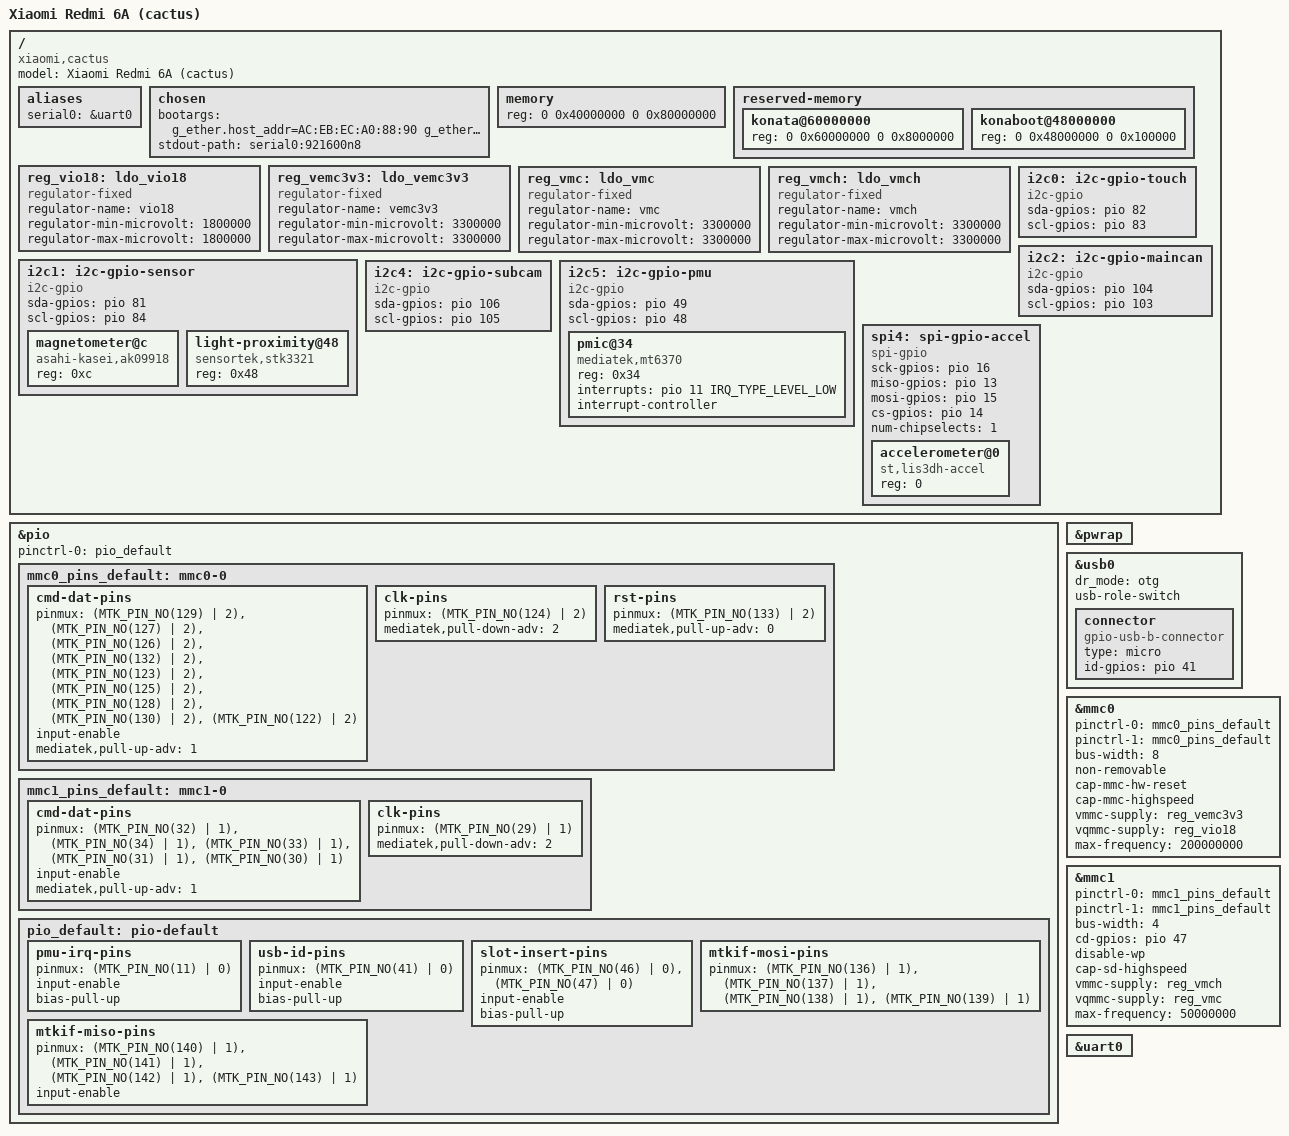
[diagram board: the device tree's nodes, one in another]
// SPDX-License-Identifier: GPL-2.0

/dts-v1/;

#include "mt6762m.dtsi"

#include <dt-bindings/gpio/gpio.h>
#include <dt-bindings/input/input.h>
#include <dt-bindings/pinctrl/mt65xx.h>

/ {
	compatible = "xiaomi,cactus", "mediatek,mt6762m", "mediatek,mt6765";
	model = "Xiaomi Redmi 6A (cactus)";

	aliases {
		serial0 = &uart0;
	};

	chosen {
		bootargs = "\
g_ether.host_addr=AC:EB:EC:A0:88:90 g_ether.dev_addr=DE:AD:BE:EF:47:77 \
clk_ignore_unused earlycon console=ttyS0,921600 root=/dev/mmcblk1p2 rootwait";
		stdout-path = "serial0:921600n8";
	};

	memory {
		device_type = "memory";
		reg = <0 0x40000000 0 0x80000000>;
	};

	reserved-memory {
		#address-cells = <2>;
		#size-cells = <2>;
		ranges;

		/* konata's 128 MiB of reserved memory */
		konata@60000000 {
			reg = <0 0x60000000 0 0x8000000>;
		};

		/* My special bootloader */
		konaboot@48000000 {
			reg = <0 0x48000000 0 0x100000>;
		};
	};

	/* dummy regulators -- needs to be from the MT6357 PMIC node! */
	reg_vio18: ldo_vio18 {
		compatible = "regulator-fixed";
		regulator-name = "vio18";
		regulator-min-microvolt = <1800000>;
		regulator-max-microvolt = <1800000>;
	};

	reg_vemc3v3: ldo_vemc3v3 {
		compatible = "regulator-fixed";
		regulator-name = "vemc3v3";
		regulator-min-microvolt = <3300000>;
		regulator-max-microvolt = <3300000>;
	};

	reg_vmc: ldo_vmc {
		compatible = "regulator-fixed";
		regulator-name = "vmc";
		regulator-min-microvolt = <3300000>;
		regulator-max-microvolt = <3300000>;
	};

	reg_vmch: ldo_vmch {
		compatible = "regulator-fixed";
		regulator-name = "vmch";
		regulator-min-microvolt = <3300000>;
		regulator-max-microvolt = <3300000>;
	};

	/* i2c gpio -- need to make the hw i2c work */
	i2c0: i2c-gpio-touch {
		compatible = "i2c-gpio";
		sda-gpios = <&pio 82 (GPIO_ACTIVE_HIGH|GPIO_OPEN_DRAIN)>;
		scl-gpios = <&pio 83 (GPIO_ACTIVE_HIGH|GPIO_OPEN_DRAIN)>;
	};

	i2c1: i2c-gpio-sensor {
		compatible = "i2c-gpio";
		sda-gpios = <&pio 81 (GPIO_ACTIVE_HIGH|GPIO_OPEN_DRAIN)>;
		scl-gpios = <&pio 84 (GPIO_ACTIVE_HIGH|GPIO_OPEN_DRAIN)>;
	};

	i2c2: i2c-gpio-maincan {
		compatible = "i2c-gpio";
		sda-gpios = <&pio 104 (GPIO_ACTIVE_HIGH|GPIO_OPEN_DRAIN)>;
		scl-gpios = <&pio 103 (GPIO_ACTIVE_HIGH|GPIO_OPEN_DRAIN)>;
	};

	i2c4: i2c-gpio-subcam {
		compatible = "i2c-gpio";
		sda-gpios = <&pio 106 (GPIO_ACTIVE_HIGH|GPIO_OPEN_DRAIN)>;
		scl-gpios = <&pio 105 (GPIO_ACTIVE_HIGH|GPIO_OPEN_DRAIN)>;
	};

	i2c5: i2c-gpio-pmu {
		compatible = "i2c-gpio";
		sda-gpios = <&pio 49 (GPIO_ACTIVE_HIGH|GPIO_OPEN_DRAIN)>;
		scl-gpios = <&pio 48 (GPIO_ACTIVE_HIGH|GPIO_OPEN_DRAIN)>;
	};

	/* spi gpio --- need to make the hw spi work */
	spi4: spi-gpio-accel {
		compatible = "spi-gpio";
		sck-gpios = <&pio 16 0>;
		miso-gpios = <&pio 13 0>;
		mosi-gpios = <&pio 15 0>;
		cs-gpios = <&pio 14 0>;
		num-chipselects = <1>;
	};
};

&pio {
	pinctrl-0 = <&pio_default>;
	pinctrl-names = "default";

	mmc0_pins_default: mmc0-0 {
		cmd-dat-pins {
			pinmux = <(MTK_PIN_NO(129) | 2)>,
			         <(MTK_PIN_NO(127) | 2)>,
			         <(MTK_PIN_NO(126) | 2)>,
			         <(MTK_PIN_NO(132) | 2)>,
			         <(MTK_PIN_NO(123) | 2)>,
			         <(MTK_PIN_NO(125) | 2)>,
			         <(MTK_PIN_NO(128) | 2)>,
			         <(MTK_PIN_NO(130) | 2)>,
			         <(MTK_PIN_NO(122) | 2)>;
			input-enable;
			mediatek,pull-up-adv = <1>;
		};
		clk-pins {
			pinmux = <(MTK_PIN_NO(124) | 2)>;
			mediatek,pull-down-adv = <2>;
		};
		rst-pins {
			pinmux = <(MTK_PIN_NO(133) | 2)>;
			mediatek,pull-up-adv = <0>;
		};
	};

	mmc1_pins_default: mmc1-0 {
		cmd-dat-pins {
			pinmux = <(MTK_PIN_NO(32) | 1)>,
			         <(MTK_PIN_NO(34) | 1)>,
			         <(MTK_PIN_NO(33) | 1)>,
			         <(MTK_PIN_NO(31) | 1)>,
			         <(MTK_PIN_NO(30) | 1)>;
			input-enable;
			mediatek,pull-up-adv = <1>;
		};
		clk-pins {
			pinmux = <(MTK_PIN_NO(29) | 1)>;
			mediatek,pull-down-adv = <2>;
		};
	};

	pio_default: pio-default {
		pmu-irq-pins {
			pinmux = <(MTK_PIN_NO(11) | 0)>;
			input-enable;
			bias-pull-up;
		};

		usb-id-pins {
			pinmux = <(MTK_PIN_NO(41) | 0)>; /* 1 for IDDIG */
			input-enable;
			bias-pull-up;
		};

		slot-insert-pins {
			pinmux = <(MTK_PIN_NO(46) | 0)>, /* SIM2 */
			         <(MTK_PIN_NO(47) | 0)>; /* SIM1/microSD */
			input-enable;
			bias-pull-up;
		};

		mtkif-mosi-pins {
			pinmux = <(MTK_PIN_NO(136) | 1)>,
			         <(MTK_PIN_NO(137) | 1)>,
			         <(MTK_PIN_NO(138) | 1)>,
			         <(MTK_PIN_NO(139) | 1)>;
		};
		mtkif-miso-pins {
			pinmux = <(MTK_PIN_NO(140) | 1)>,
			         <(MTK_PIN_NO(141) | 1)>,
			         <(MTK_PIN_NO(142) | 1)>,
			         <(MTK_PIN_NO(143) | 1)>;
			input-enable;
		};
	};
};

&i2c0 {
	status = "okay";

	/* touchscreen (xxx @ 0x38) */
};

&i2c1 {
	status = "okay";
	#address-cells = <1>;
	#size-cells = <0>;

	magnetometer@c {
		compatible = "asahi-kasei,ak09918";
		reg = <0xc>;
	};

	light-proximity@48 {
		compatible = "sensortek,stk3321";
		reg = <0x48>;
	};
};

&i2c2 {
	status = "okay";

	/* main camera */
};

&i2c4 {
	status = "okay";

	/* front camera */
};

&i2c5 {
	status = "okay";
	#address-cells = <1>;
	#size-cells = <0>;

	pmic@34 {
		compatible = "mediatek,mt6370";
		reg = <0x34>;
		interrupts = <&pio 11 IRQ_TYPE_LEVEL_LOW>;
		interrupt-controller;
		#interrupt-cells = <1>;
	};

	/* the 0x4e is for some "type-c" thing */
};

&spi4 {
	status = "okay";
	#address-cells = <1>;
	#size-cells = <0>;

	accelerometer@0 {
		compatible = "st,lis3dh-accel";
		reg = <0>;
	};
};

&pwrap {
	status = "okay";

	/* MT6357 PMIC */
};

&usb0 {
	status = "okay";
	dr_mode = "otg";
	usb-role-switch;

	connector {
		compatible = "gpio-usb-b-connector", "usb-b-connector";
		type = "micro";
		id-gpios = <&pio 41 GPIO_ACTIVE_HIGH>;
		/* vbus-supply = <&usb_vbus>; <-- TODO for MT6370 */
	};
};

&mmc0 {
	status = "okay";
	pinctrl-0 = <&mmc0_pins_default>;
	pinctrl-1 = <&mmc0_pins_default>;
	pinctrl-names = "default", "state_uhs";
	bus-width = <8>;
	non-removable;
	cap-mmc-hw-reset;
	cap-mmc-highspeed;
	//mmc-ddr-1_8v;
	//mmc-hs200-1_8v;
	vmmc-supply = <&reg_vemc3v3>;
	vqmmc-supply = <&reg_vio18>;
	max-frequency = <200000000>;
};

&mmc1 {
	status = "okay";
	pinctrl-0 = <&mmc1_pins_default>;
	pinctrl-1 = <&mmc1_pins_default>;
	pinctrl-names = "default", "state_uhs";
	bus-width = <4>;
	cd-gpios = <&pio 47 GPIO_ACTIVE_HIGH>;
	disable-wp;
	cap-sd-highspeed;
	vmmc-supply = <&reg_vmch>;
	vqmmc-supply = <&reg_vmc>;
	max-frequency = <50000000>;
};

&uart0 {
	status = "okay";
};
